# nrf5340 register map
Vendor: Nordic Semiconductor; Series: nrf53; File version: 1
CPU: CM33 r0p2, little endian, MPU, FPU, 3 interrupt priority bits
Registers are 32-bit, read-write, reset 0x0 unless marked. A register's access mark holds for its fields unless they carry their own. Offsets are from the block's base; [hi:lo] are bit positions; lines under a group give offsets from that group; {n}, {i} and the like mark numbered series; 'fields as' and 'values as' point back to an identical list.

## SPU_S — System Protection Unit
Base 0x50003000
0x100 EVENTS_RAMACCERR — A security violation has been detected for the RAM memory space
  [0] EVENTS_RAMACCERR
    0=NotGenerated (Event not generated); 1=Generated (Event generated)
0x104 EVENTS_FLASHACCERR — A security violation has been detected for the Flash memory space
  [0] EVENTS_FLASHACCERR
    values as EVENTS_RAMACCERR.EVENTS_RAMACCERR
0x108 EVENTS_PERIPHACCERR — A security violation has been detected on one or several peripherals
  [0] EVENTS_PERIPHACCERR
    values as EVENTS_RAMACCERR.EVENTS_RAMACCERR
0x10C EVENTS_XIPACCERR — A security violation has been detected while accessing the eXecute In Place (XIP) address space
  [0] EVENTS_XIPACCERR
    values as EVENTS_RAMACCERR.EVENTS_RAMACCERR
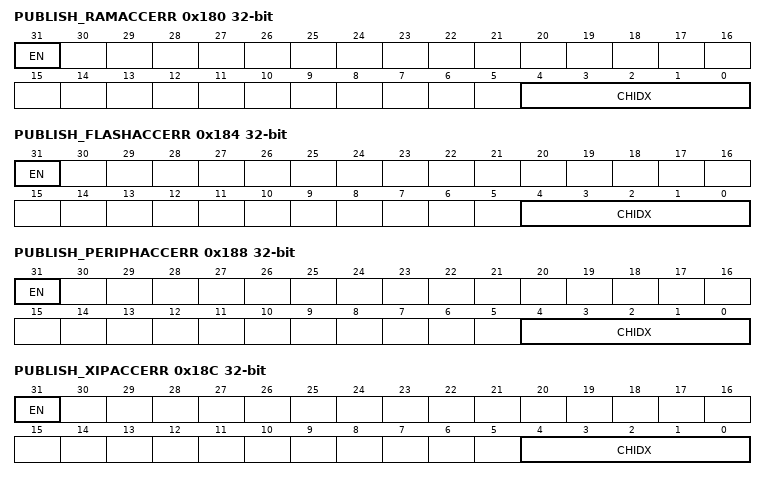
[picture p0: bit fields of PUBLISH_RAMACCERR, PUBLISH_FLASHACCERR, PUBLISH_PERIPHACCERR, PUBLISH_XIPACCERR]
0x180 PUBLISH_RAMACCERR — Publish configuration for event RAMACCERR
  [31] EN
    0=Disabled (Disable publishing); 1=Enabled (Enable publishing)
  [4:0] CHIDX — Channel that event RAMACCERR will publish to.
0x184 PUBLISH_FLASHACCERR — Publish configuration for event FLASHACCERR
  [31] EN
    values as PUBLISH_RAMACCERR.EN
  [4:0] CHIDX — Channel that event FLASHACCERR will publish to.
0x188 PUBLISH_PERIPHACCERR — Publish configuration for event PERIPHACCERR
  [31] EN
    values as PUBLISH_RAMACCERR.EN
  [4:0] CHIDX — Channel that event PERIPHACCERR will publish to.
0x18C PUBLISH_XIPACCERR — Publish configuration for event XIPACCERR
  [31] EN
    values as PUBLISH_RAMACCERR.EN
  [4:0] CHIDX — Channel that event XIPACCERR will publish to.
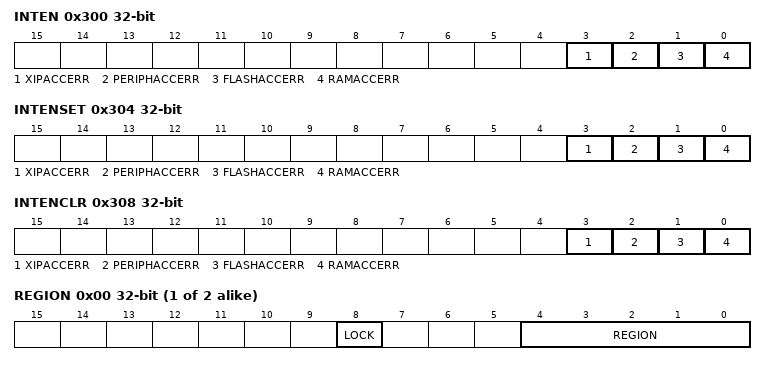
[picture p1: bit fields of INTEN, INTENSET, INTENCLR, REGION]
0x300 INTEN — Enable or disable interrupt
  [all] fields
    0=Disabled; 1=Enabled
  [3] XIPACCERR — Enable or disable interrupt for event XIPACCERR
  [2] PERIPHACCERR — Enable or disable interrupt for event PERIPHACCERR
  [1] FLASHACCERR — Enable or disable interrupt for event FLASHACCERR
  [0] RAMACCERR — Enable or disable interrupt for event RAMACCERR
0x304 INTENSET — Enable interrupt
  [all] fields
    on read: 0=Disabled (Read: Disabled); 1=Enabled (Read: Enabled) | on write: 1=Set (Enable)
  [3] XIPACCERR — Write '1' to enable interrupt for event XIPACCERR
  [2] PERIPHACCERR — Write '1' to enable interrupt for event PERIPHACCERR
  [1] FLASHACCERR — Write '1' to enable interrupt for event FLASHACCERR
  [0] RAMACCERR — Write '1' to enable interrupt for event RAMACCERR
0x308 INTENCLR — Disable interrupt
  [all] fields
    on read: 0=Disabled (Read: Disabled); 1=Enabled (Read: Enabled) | on write: 1=Clear (Disable)
  [3] XIPACCERR — Write '1' to disable interrupt for event XIPACCERR
  [2] PERIPHACCERR — Write '1' to disable interrupt for event PERIPHACCERR
  [1] FLASHACCERR — Write '1' to disable interrupt for event FLASHACCERR
  [0] RAMACCERR — Write '1' to disable interrupt for event RAMACCERR
0x400 CAP ro reset 0x1 — Show implemented features for the current device
  [0] TZM — Show ARM TrustZone status
    0=NotAvailable (ARM TrustZone support not available); 1=Enabled (ARM TrustZone support is available)
{0x440+4i} EXTDOMAIN[{i}] (i=0..1) group — Unspecified
  0x00 PERM reset 0x2 — Description cluster: Access for bus access generated from the external domain n List capabilities of the external domain n
    [8] LOCK
      0=Unlocked (This register can be updated); 1=Locked (The content of this register can't be changed until the next reset)
    [4] SECATTR — Peripheral security mapping
      0=NonSecure (Bus accesses from this domain have the Non Secure Attribute set); 1=Secure (Bus accesses from this domain have Secure Attribute set)
    [1:0] SECUREMAPPING — Define configuration capabilities for TrustZone-M secure attribute
      0=NonSecure (The bus access from this external domain always have the Non-Secure attribute set); 1=Secure (The bus access from this external domain always have the Secure attribute set); 2=UserSelectable (Non-Secure or Secure attribute for bus access from this domain is defined by the EXTDOMAIN[n].PERM register)
{0x480+8i} DPPI[{i}] (i=0..0) group — Unspecified
  0x00 PERM reset 0xFFFFFFFF — Description cluster: Select between Secure and Non-Secure attribute for the DPPI channels. Only a Secure peripheral can publish or subscribe to a channel with Secure attribute set.
    [n] CHANNEL{n} (n=0..31) — Select secure attribute.
      1=Secure (Channel{n} has its Secure attribute set); 0=NonSecure (Channel{n} has its Non-Secure attribute set)
  0x04 LOCK — Description cluster: Prevent further modification of the corresponding PERM register
    [0] LOCK
      1=Locked (DPPI[n].PERM register can't be changed until next reset); 0=Unlocked (DPPI[n].PERM register content can be changed)
{0x4C0+8i} GPIOPORT[{i}] (i=0..0) group — Unspecified
  0x00 PERM reset 0xFFFFFFFF — Description cluster: Select between Secure and Non-Secure attribute for pins 0 to 31 of port n. Only a Secure peripheral access a pin with Secure attribute set.
    [1] PIN1 — Select secure attribute attribute for PIN1.
      1=Secure (Pin1 has its Secure attribute set); 0=NonSecure (Pin1 has its Non-Secure attribute set)
    [0] PIN0 — Select secure attribute attribute for PIN0.
      1=Secure (Pin0 has its Secure attribute set); 0=NonSecure (Pin0 has its Non-Secure attribute set)
  0x04 LOCK — Description cluster: Prevent further modification of the corresponding PERM register
    [0] LOCK
      1=Locked (GPIOPORT[n].PERM register can't be changed until next reset); 0=Unlocked (GPIOPORT[n].PERM register content can be changed)
{0x500+8i} FLASHNSC[{i}] (i=0..1) group — Unspecified
  0x00 REGION — Description cluster: Define which FLASH region can contains the Non-Secure Callable (NSC) region n
    [8] LOCK
      values as EXTDOMAIN[0].PERM.LOCK
    [4:0] REGION — Region number
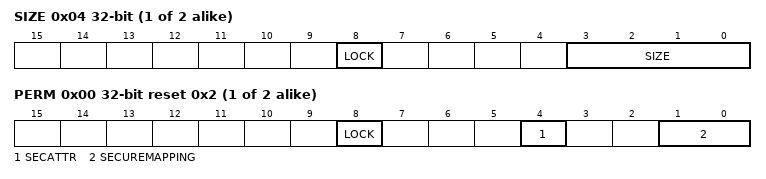
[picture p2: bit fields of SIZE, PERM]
  0x04 SIZE — Description cluster: Define the size of the Non-Secure Callable (NSC) region n
    [8] LOCK
      values as EXTDOMAIN[0].PERM.LOCK
    [3:0] SIZE — Size of the Non-Secure Callable (NSC) region n
      0=Disabled (The region n is not defined as a Non Secure Callable region. Normal security attributes (Secure or Non-Secure) are enforced); 1=The region n is defined as Non-Secure Callable with a 32-byte size; 2=The region n is defined as Non-Secure Callable with a 64-byte size; 3=The region n is defined as Non-Secure Callable with a 128-byte size; 4=The region n is defined as Non-Secure Callable with a 256-byte size; 5=The region n is defined as Non-Secure Callable with a 512-byte size; 6=The region n is defined as Non-Secure Callable with a 1024-byte size; 7=The region n is defined as Non-Secure Callable with a 2048-byte size; 8=The region n is defined as Non-Secure Callable with a 4096-byte size
{0x540+8i} RAMNSC[{i}] (i=0..1) group — Unspecified
  0x00 REGION — Description cluster: Define which RAM region can contains the Non-Secure Callable (NSC) region n
    [8] LOCK
      values as EXTDOMAIN[0].PERM.LOCK
    [3:0] REGION — Region number
  0x04 SIZE — Description cluster: Define the size of the Non-Secure Callable (NSC) region n
    fields as FLASHNSC[0].SIZE
{0x580+4i} XIPREGION[{i}] (i=0..0) group — Unspecified
  0x00 PERM reset 0x7 — Description cluster: Access permissions for XIP region n
    [8] LOCK
      values as EXTDOMAIN[0].PERM.LOCK
    [2] READ — Configure read permissions for XIP region n.
      1=Enable (Allow read operation from XIP region n); 0=Disable (Block read operation from XIP region n)
    [1] WRITE — Configure write permission for XIP region n.
      1=Enable (Allow write operation to region n); 0=Disable (Block write operation to region n)
    [0] EXECUTE — Configure instruction fetch permissions from XIP region n.
      1=Enable (Allow execution of instruction fetches from XIP region n); 0=Disable (Block request to execute instruction fetches from XIP region n)
{0x600+4i} FLASHREGION[{i}] (i=0..31) group — Unspecified
  0x00 PERM reset 0x17 — Description cluster: Access permissions for FLASH region n
    [8] LOCK
      values as EXTDOMAIN[0].PERM.LOCK
    [4] SECATTR — Security attribute for FLASH region n
      0=Non_Secure (FLASH region n security attribute is Non-Secure); 1=Secure (FLASH region n security attribute is Secure)
    [2] READ — Configure read permissions for FLASH region n.
      1=Enable (Allow read operation from FLASH region n); 0=Disable (Block read operation from FLASH region n)
    [1] WRITE — Configure write permission for FLASH region n.
      values as XIPREGION[0].PERM.WRITE
    [0] EXECUTE — Configure instruction fetch permissions from FLASH region n.
      1=Enable (Allow instruction fetches from FLASH region n); 0=Disable (Block instruction fetches from FLASH region n)
{0x700+4i} RAMREGION[{i}] (i=0..31) group — Unspecified
  0x00 PERM reset 0x17 — Description cluster: Access permissions for RAM region n
    [8] LOCK
      values as EXTDOMAIN[0].PERM.LOCK
    [4] SECATTR — Security attribute for RAM region n
      0=Non_Secure (RAM region n security attribute is Non-Secure); 1=Secure (RAM region n security attribute is Secure)
    [2] READ — Configure read permissions for RAM region n.
      1=Enable (Allow read operation from RAM region n); 0=Disable (Block read operation from RAM region n)
    [1] WRITE — Configure write permission for RAM region n.
      1=Enable (Allow write operation to RAM region n); 0=Disable (Block write operation to RAM region n)
    [0] EXECUTE — Configure instruction fetch permissions from RAM region n.
      1=Enable (Allow instruction fetches from RAM region n); 0=Disable (Block instruction fetches from RAM region n)
{0x800+4i} PERIPHID[{i}] (i=0..26) group — Unspecified
  0x00 PERM reset 0x12 — Description cluster: List capabilities and Access permissions for the peripheral with ID n
    [31] PRESENT — Indicate if a peripheral is present with ID n.
      0=NotPresent (Peripheral is not present); 1=IsPresent (Peripheral is present)
    [8] LOCK
      values as EXTDOMAIN[0].PERM.LOCK
    [5] DMASEC — Security attribution for the DMA transfer
      1=Secure (DMA transfers initiated by this peripheral have the Secure attribute set.); 0=NonSecure (DMA transfers initiated by this peripheral have the Non-Secure attribute set.)
    [4] SECATTR — Peripheral security mapping
      1=Secure (Peripheral is mapped in Secure Peripheral Address space.); 0=NonSecure (If SECUREMAPPING == UserSelectable: Peripheral is mapped in Non-Secure Peripheral Address space. If SECUREMAPPING == Split: Peripheral is mapped in Non-Secure and Secure Peripheral Address space.)
    [3:2] DMA — Indicate if the peripheral has DMA capabilities and if DMA transfer can be assigned to a different security attribute than the peripheral itself
      0=NoDMA (Peripheral has no DMA capability); 1=NoSeparateAttribute (Peripheral has DMA and DMA transfers always have the same security attribute as assigned to the peripheral); 2=SeparateAttribute (Peripheral has DMA and DMA transfers can have a different security attribute than the one assigned to the peripheral)
    [1:0] SECUREMAPPING — Define configuration capabilities for TrustZone-M secure attribute
      0=NonSecure (This peripheral is always accessible as a Non-Secure peripheral); 1=Secure (This peripheral is always accessible as a Secure peripheral); 2=UserSelectable (Non-Secure or Secure attribute for this peripheral is defined by the PERIPHID[n].PERM register); 3=Split (This peripheral implements the split security mechanism. Non-Secure or Secure attribute for this peripheral is defined by the PERIPHID[n].PERM register)
